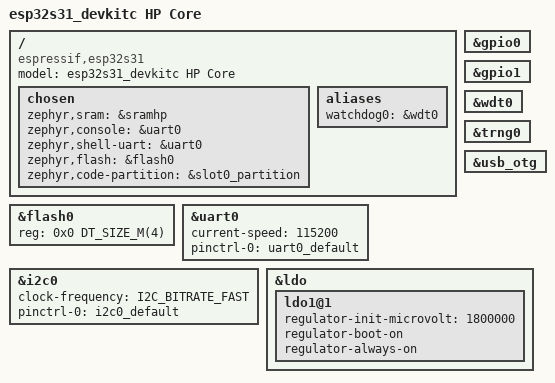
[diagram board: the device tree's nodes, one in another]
/*
 * Copyright (c) 2026 Espressif Systems (Shanghai) Co., Ltd.
 *
 * SPDX-License-Identifier: Apache-2.0
 */

/dts-v1/;

#include <espressif/esp32s31/esp32s31.dtsi>
#include "esp32s31_devkitc_hpcore-pinctrl.dtsi"
#include <espressif/partitions_0x2000_default_4M.dtsi>

/ {
	model = "esp32s31_devkitc HP Core";
	compatible = "espressif,esp32s31";

	chosen {
		zephyr,sram = &sramhp;
		zephyr,console = &uart0;
		zephyr,shell-uart = &uart0;
		zephyr,flash = &flash0;
		zephyr,code-partition = &slot0_partition;
	};

	aliases {
		watchdog0 = &wdt0;
	};
};

&flash0 {
	reg = <0x0 DT_SIZE_M(4)>;
	ranges = <0x0 0x0 DT_SIZE_M(4)>;
};

&uart0 {
	status = "okay";
	current-speed = <115200>;
	pinctrl-0 = <&uart0_default>;
	pinctrl-names = "default";
};

&i2c0 {
	status = "okay";
	clock-frequency = <I2C_BITRATE_FAST>;
	pinctrl-0 = <&i2c0_default>;
	pinctrl-names = "default";
};

&gpio0 {
	status = "okay";
};

&gpio1 {
	status = "okay";
};

&wdt0 {
	status = "okay";
};

&trng0 {
	status = "okay";
};

zephyr_udc0: &usb_otg {
	status = "okay";
};

/* Internal LDO channel 1 powers the on-board PSRAM at 1.8 V. */
&ldo {
	status = "okay";

	ldo1@1 {
		regulator-init-microvolt = <1800000>;
		regulator-boot-on;
		regulator-always-on;
	};
};
